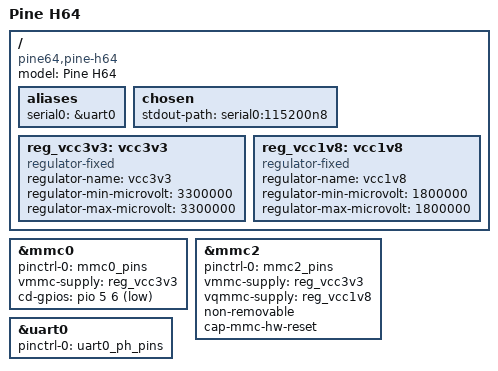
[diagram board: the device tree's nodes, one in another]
/*
 * Copyright (c) 2017 Icenowy Zheng <icenowy@aosc.io>
 *
 * SPDX-License-Identifier: (GPL-2.0+ or MIT)
 */

/dts-v1/;

#include "sun50i-h6.dtsi"

#include <dt-bindings/gpio/gpio.h>

/ {
	model = "Pine H64";
	compatible = "pine64,pine-h64", "allwinner,sun50i-h6";

	aliases {
		serial0 = &uart0;
	};

	chosen {
		stdout-path = "serial0:115200n8";
	};

	reg_vcc3v3: vcc3v3 {
		compatible = "regulator-fixed";
		regulator-name = "vcc3v3";
		regulator-min-microvolt = <3300000>;
		regulator-max-microvolt = <3300000>;
	};

	reg_vcc1v8: vcc1v8 {
		compatible = "regulator-fixed";
		regulator-name = "vcc1v8";
		regulator-min-microvolt = <1800000>;
		regulator-max-microvolt = <1800000>;
	};
};

&mmc0 {
	pinctrl-names = "default";
	pinctrl-0 = <&mmc0_pins>;
	vmmc-supply = <&reg_vcc3v3>;
	cd-gpios = <&pio 5 6 GPIO_ACTIVE_LOW>;
	status = "okay";
};

&mmc2 {
	pinctrl-names = "default";
	pinctrl-0 = <&mmc2_pins>;
	vmmc-supply = <&reg_vcc3v3>;
	vqmmc-supply = <&reg_vcc1v8>;
	non-removable;
	cap-mmc-hw-reset;
	status = "okay";
};

&uart0 {
	pinctrl-names = "default";
	pinctrl-0 = <&uart0_ph_pins>;
	status = "okay";
};
